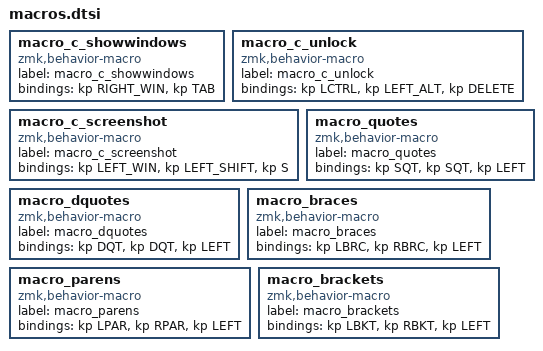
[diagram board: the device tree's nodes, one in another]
macro_c_showwindows: macro_c_showwindows{
compatible = "zmk,behavior-macro";
label = "macro_c_showwindows";
#binding-cells = <0>;
bindings = <&kp RIGHT_WIN>, <&kp TAB>;
};
macro_c_unlock: macro_c_unlock{
compatible = "zmk,behavior-macro";
label = "macro_c_unlock";
#binding-cells = <0>;
bindings = <&kp LCTRL>, <&kp LEFT_ALT>, <&kp DELETE>;
};
macro_c_screenshot: macro_c_screenshot{
compatible = "zmk,behavior-macro";
label = "macro_c_screenshot";
#binding-cells = <0>;
bindings = <&kp LEFT_WIN>, <&kp LEFT_SHIFT>, <&kp S>;
};
macro_quotes: macro_quotes{
compatible = "zmk,behavior-macro";
label = "macro_quotes";
#binding-cells = <0>;
bindings = <&kp SQT>, <&kp SQT>, <&kp LEFT>;
};
macro_dquotes: macro_dquotes{
compatible = "zmk,behavior-macro";
label = "macro_dquotes";
#binding-cells = <0>;
bindings = <&kp DQT>, <&kp DQT>, <&kp LEFT>;
};
macro_braces: macro_braces{
compatible = "zmk,behavior-macro";
label = "macro_braces";
#binding-cells = <0>;
bindings = <&kp LBRC>, <&kp RBRC>, <&kp LEFT>;
};
macro_parens: macro_parens{
compatible = "zmk,behavior-macro";
label = "macro_parens";
#binding-cells = <0>;
bindings = <&kp LPAR>, <&kp RPAR>, <&kp LEFT>;
};
macro_brackets: macro_brackets{
compatible = "zmk,behavior-macro";
label = "macro_brackets";
#binding-cells = <0>;
bindings = <&kp LBKT>, <&kp RBKT>, <&kp LEFT>;
};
